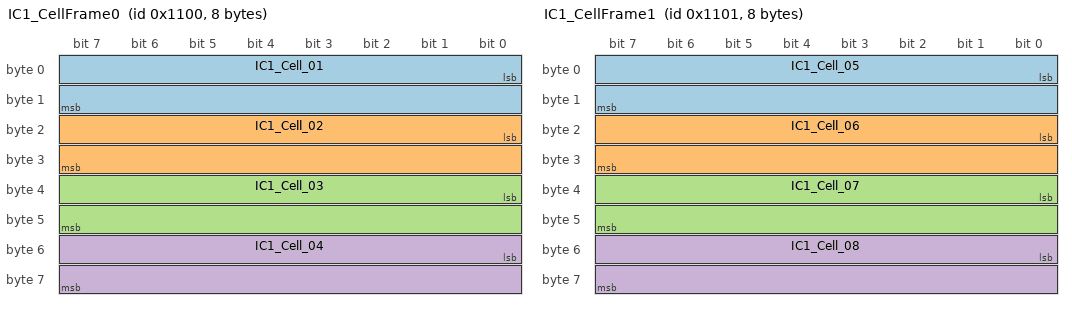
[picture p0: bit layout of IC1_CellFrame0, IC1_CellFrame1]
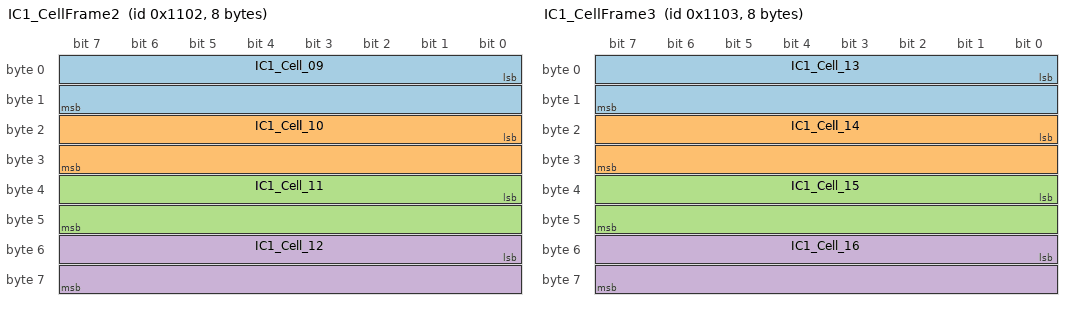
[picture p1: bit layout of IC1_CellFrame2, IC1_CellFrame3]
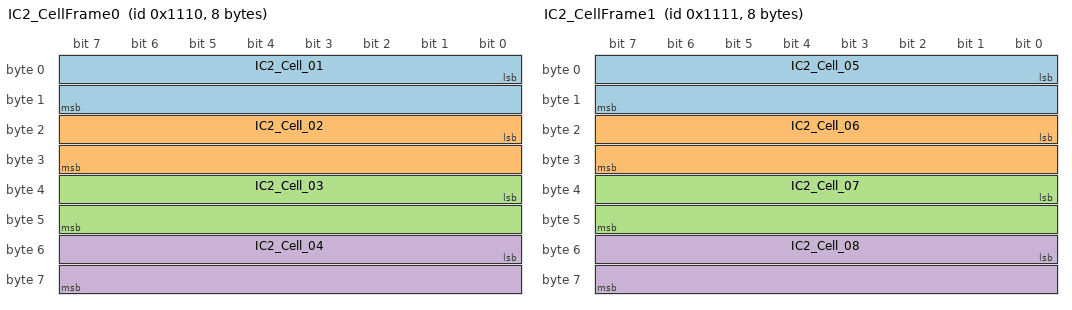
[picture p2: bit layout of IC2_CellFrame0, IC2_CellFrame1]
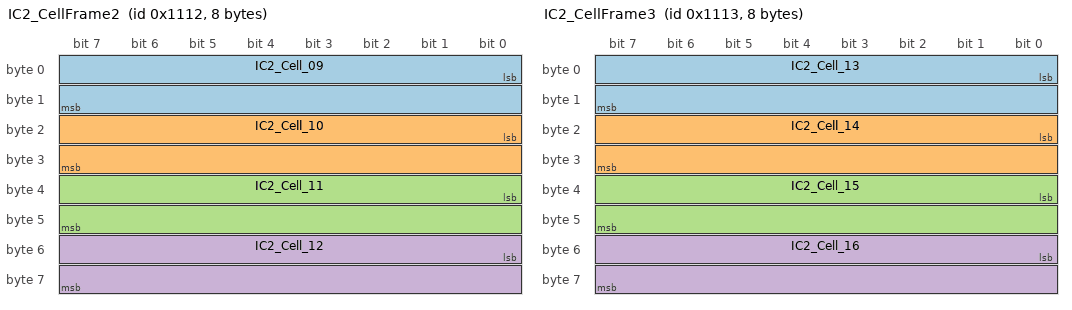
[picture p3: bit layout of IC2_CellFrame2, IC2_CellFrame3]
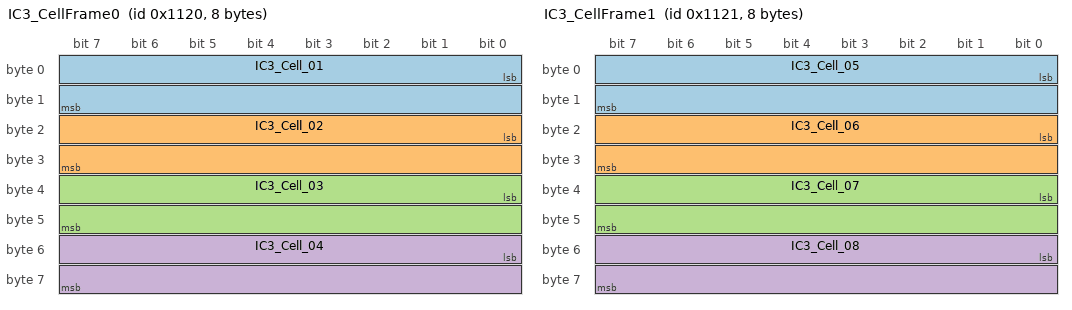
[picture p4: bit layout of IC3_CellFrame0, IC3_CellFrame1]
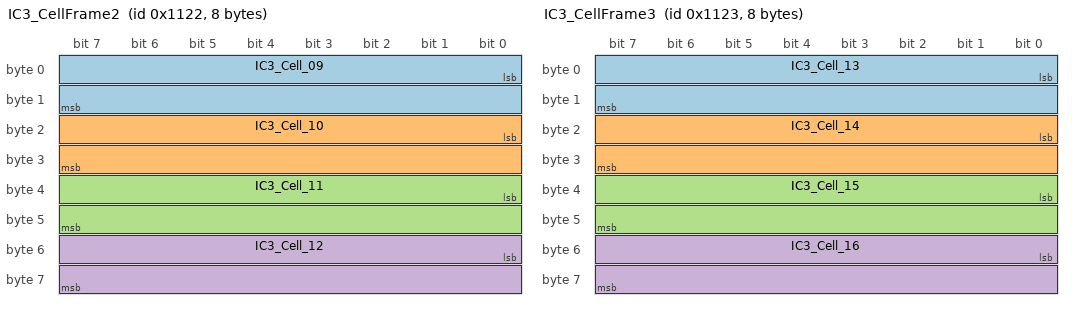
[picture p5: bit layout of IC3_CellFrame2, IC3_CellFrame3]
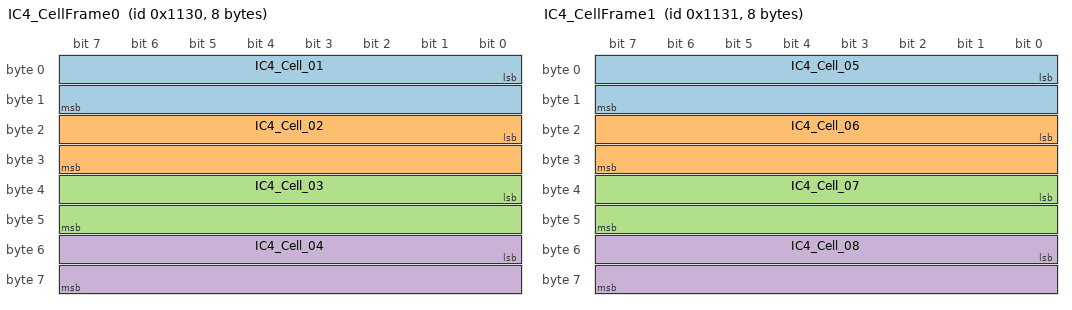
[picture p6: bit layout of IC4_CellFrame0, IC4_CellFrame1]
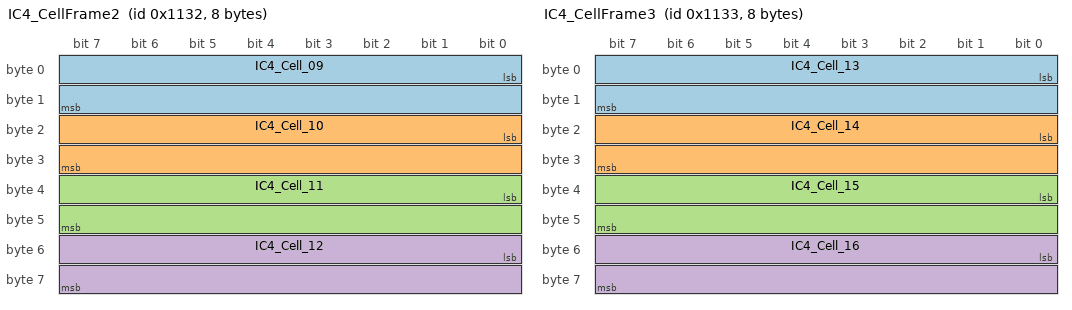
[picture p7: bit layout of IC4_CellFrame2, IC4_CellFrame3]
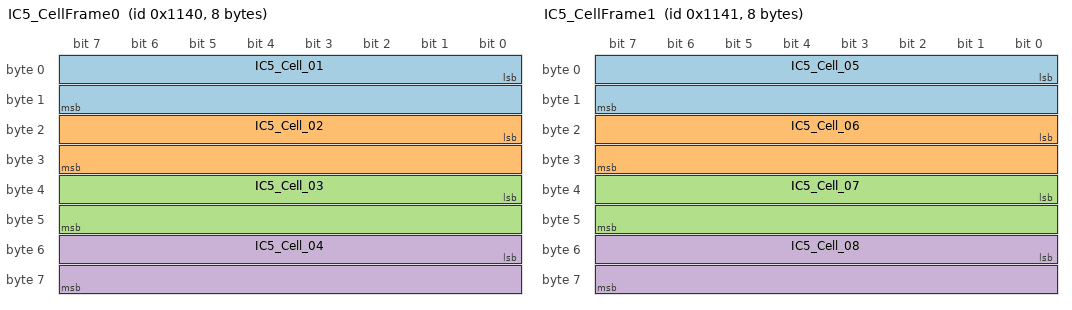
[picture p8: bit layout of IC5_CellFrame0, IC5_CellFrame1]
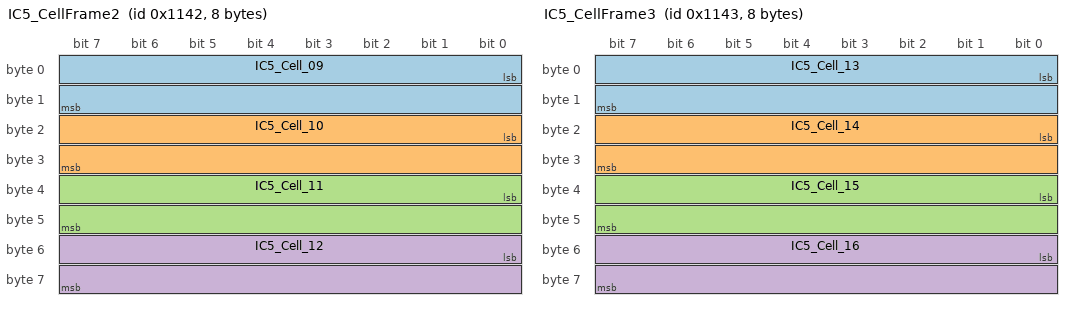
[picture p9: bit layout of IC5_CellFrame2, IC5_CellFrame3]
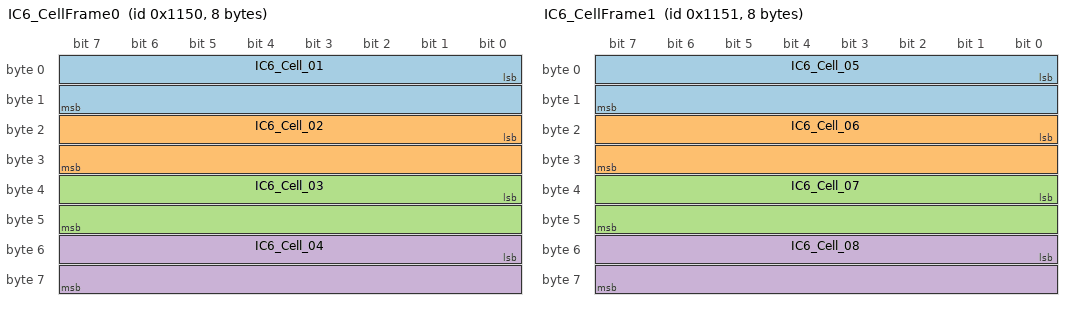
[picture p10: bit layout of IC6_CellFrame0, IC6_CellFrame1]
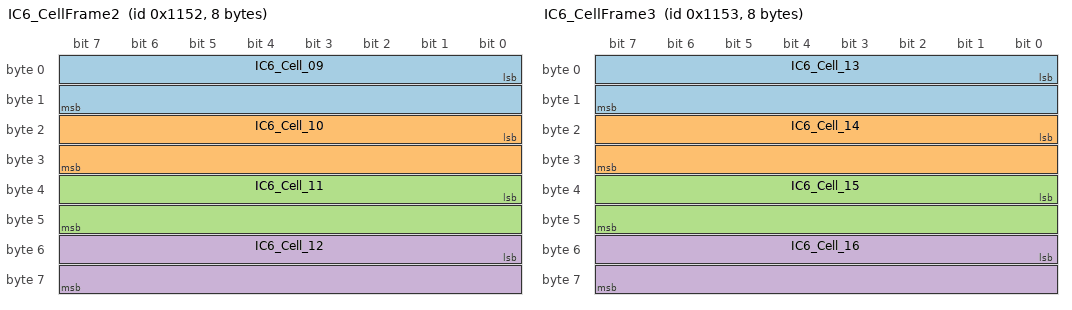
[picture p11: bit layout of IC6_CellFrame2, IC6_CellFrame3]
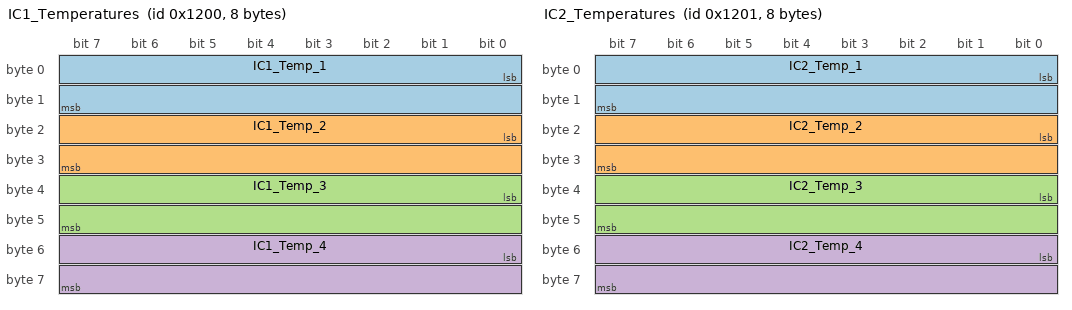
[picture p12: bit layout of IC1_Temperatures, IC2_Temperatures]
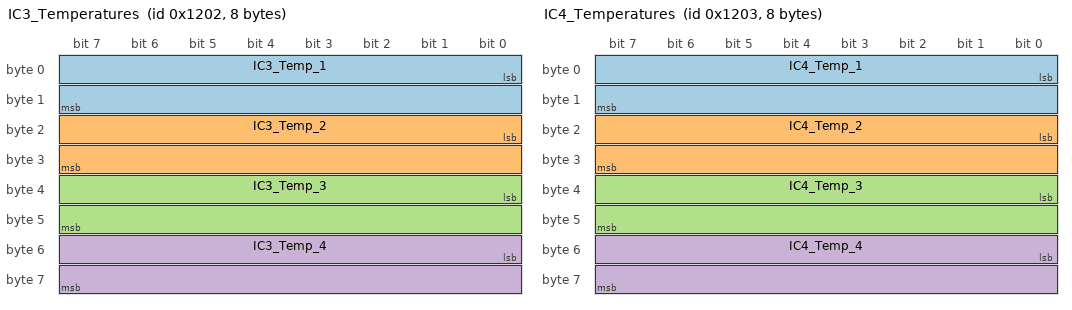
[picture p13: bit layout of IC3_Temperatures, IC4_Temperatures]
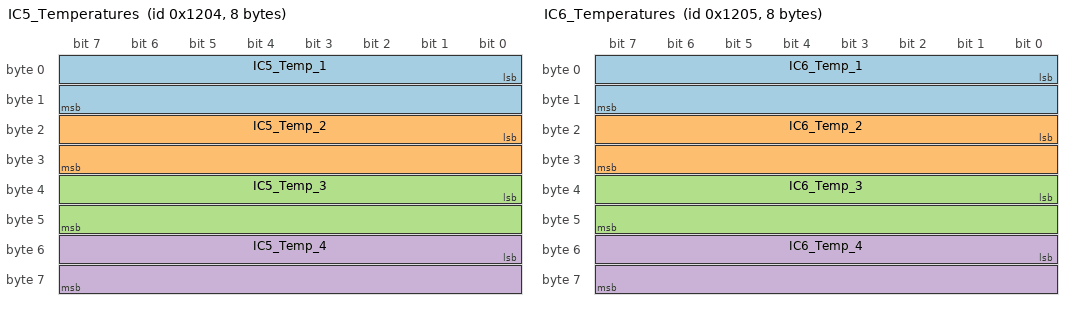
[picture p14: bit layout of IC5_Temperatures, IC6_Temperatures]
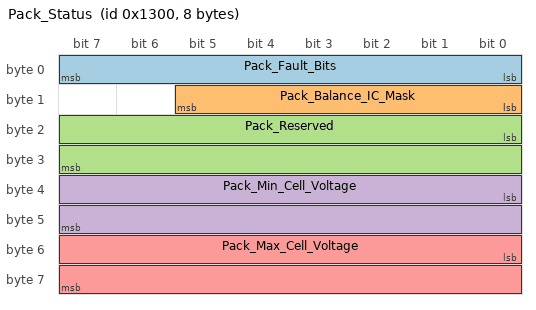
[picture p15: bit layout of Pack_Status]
VERSION ""

NS_ :

BS_:

BU_: BMS Host

BO_ 0x1100 IC1_CellFrame0: 8 BMS
 SG_ IC1_Cell_01 : 0|16@1+ (0.0001,0) [0|6.5535] "V" Host
 SG_ IC1_Cell_02 : 16|16@1+ (0.0001,0) [0|6.5535] "V" Host
 SG_ IC1_Cell_03 : 32|16@1+ (0.0001,0) [0|6.5535] "V" Host
 SG_ IC1_Cell_04 : 48|16@1+ (0.0001,0) [0|6.5535] "V" Host

BO_ 0x1101 IC1_CellFrame1: 8 BMS
 SG_ IC1_Cell_05 : 0|16@1+ (0.0001,0) [0|6.5535] "V" Host
 SG_ IC1_Cell_06 : 16|16@1+ (0.0001,0) [0|6.5535] "V" Host
 SG_ IC1_Cell_07 : 32|16@1+ (0.0001,0) [0|6.5535] "V" Host
 SG_ IC1_Cell_08 : 48|16@1+ (0.0001,0) [0|6.5535] "V" Host

BO_ 0x1102 IC1_CellFrame2: 8 BMS
 SG_ IC1_Cell_09 : 0|16@1+ (0.0001,0) [0|6.5535] "V" Host
 SG_ IC1_Cell_10 : 16|16@1+ (0.0001,0) [0|6.5535] "V" Host
 SG_ IC1_Cell_11 : 32|16@1+ (0.0001,0) [0|6.5535] "V" Host
 SG_ IC1_Cell_12 : 48|16@1+ (0.0001,0) [0|6.5535] "V" Host

BO_ 0x1103 IC1_CellFrame3: 8 BMS
 SG_ IC1_Cell_13 : 0|16@1+ (0.0001,0) [0|6.5535] "V" Host
 SG_ IC1_Cell_14 : 16|16@1+ (0.0001,0) [0|6.5535] "V" Host
 SG_ IC1_Cell_15 : 32|16@1+ (0.0001,0) [0|6.5535] "V" Host
 SG_ IC1_Cell_16 : 48|16@1+ (0.0001,0) [0|6.5535] "V" Host

BO_ 0x1104 IC1_CellFrame4: 8 BMS
 SG_ IC1_Cell_17 : 0|16@1+ (0.0001,0) [0|6.5535] "V" Host

BO_ 0x1110 IC2_CellFrame0: 8 BMS
 SG_ IC2_Cell_01 : 0|16@1+ (0.0001,0) [0|6.5535] "V" Host
 SG_ IC2_Cell_02 : 16|16@1+ (0.0001,0) [0|6.5535] "V" Host
 SG_ IC2_Cell_03 : 32|16@1+ (0.0001,0) [0|6.5535] "V" Host
 SG_ IC2_Cell_04 : 48|16@1+ (0.0001,0) [0|6.5535] "V" Host

BO_ 0x1111 IC2_CellFrame1: 8 BMS
 SG_ IC2_Cell_05 : 0|16@1+ (0.0001,0) [0|6.5535] "V" Host
 SG_ IC2_Cell_06 : 16|16@1+ (0.0001,0) [0|6.5535] "V" Host
 SG_ IC2_Cell_07 : 32|16@1+ (0.0001,0) [0|6.5535] "V" Host
 SG_ IC2_Cell_08 : 48|16@1+ (0.0001,0) [0|6.5535] "V" Host

BO_ 0x1112 IC2_CellFrame2: 8 BMS
 SG_ IC2_Cell_09 : 0|16@1+ (0.0001,0) [0|6.5535] "V" Host
 SG_ IC2_Cell_10 : 16|16@1+ (0.0001,0) [0|6.5535] "V" Host
 SG_ IC2_Cell_11 : 32|16@1+ (0.0001,0) [0|6.5535] "V" Host
 SG_ IC2_Cell_12 : 48|16@1+ (0.0001,0) [0|6.5535] "V" Host

BO_ 0x1113 IC2_CellFrame3: 8 BMS
 SG_ IC2_Cell_13 : 0|16@1+ (0.0001,0) [0|6.5535] "V" Host
 SG_ IC2_Cell_14 : 16|16@1+ (0.0001,0) [0|6.5535] "V" Host
 SG_ IC2_Cell_15 : 32|16@1+ (0.0001,0) [0|6.5535] "V" Host
 SG_ IC2_Cell_16 : 48|16@1+ (0.0001,0) [0|6.5535] "V" Host

BO_ 0x1114 IC2_CellFrame4: 8 BMS
 SG_ IC2_Cell_17 : 0|16@1+ (0.0001,0) [0|6.5535] "V" Host

BO_ 0x1120 IC3_CellFrame0: 8 BMS
 SG_ IC3_Cell_01 : 0|16@1+ (0.0001,0) [0|6.5535] "V" Host
 SG_ IC3_Cell_02 : 16|16@1+ (0.0001,0) [0|6.5535] "V" Host
 SG_ IC3_Cell_03 : 32|16@1+ (0.0001,0) [0|6.5535] "V" Host
 SG_ IC3_Cell_04 : 48|16@1+ (0.0001,0) [0|6.5535] "V" Host

BO_ 0x1121 IC3_CellFrame1: 8 BMS
 SG_ IC3_Cell_05 : 0|16@1+ (0.0001,0) [0|6.5535] "V" Host
 SG_ IC3_Cell_06 : 16|16@1+ (0.0001,0) [0|6.5535] "V" Host
 SG_ IC3_Cell_07 : 32|16@1+ (0.0001,0) [0|6.5535] "V" Host
 SG_ IC3_Cell_08 : 48|16@1+ (0.0001,0) [0|6.5535] "V" Host

BO_ 0x1122 IC3_CellFrame2: 8 BMS
 SG_ IC3_Cell_09 : 0|16@1+ (0.0001,0) [0|6.5535] "V" Host
 SG_ IC3_Cell_10 : 16|16@1+ (0.0001,0) [0|6.5535] "V" Host
 SG_ IC3_Cell_11 : 32|16@1+ (0.0001,0) [0|6.5535] "V" Host
 SG_ IC3_Cell_12 : 48|16@1+ (0.0001,0) [0|6.5535] "V" Host

BO_ 0x1123 IC3_CellFrame3: 8 BMS
 SG_ IC3_Cell_13 : 0|16@1+ (0.0001,0) [0|6.5535] "V" Host
 SG_ IC3_Cell_14 : 16|16@1+ (0.0001,0) [0|6.5535] "V" Host
 SG_ IC3_Cell_15 : 32|16@1+ (0.0001,0) [0|6.5535] "V" Host
 SG_ IC3_Cell_16 : 48|16@1+ (0.0001,0) [0|6.5535] "V" Host

BO_ 0x1124 IC3_CellFrame4: 8 BMS
 SG_ IC3_Cell_17 : 0|16@1+ (0.0001,0) [0|6.5535] "V" Host

BO_ 0x1130 IC4_CellFrame0: 8 BMS
 SG_ IC4_Cell_01 : 0|16@1+ (0.0001,0) [0|6.5535] "V" Host
 SG_ IC4_Cell_02 : 16|16@1+ (0.0001,0) [0|6.5535] "V" Host
 SG_ IC4_Cell_03 : 32|16@1+ (0.0001,0) [0|6.5535] "V" Host
 SG_ IC4_Cell_04 : 48|16@1+ (0.0001,0) [0|6.5535] "V" Host

BO_ 0x1131 IC4_CellFrame1: 8 BMS
 SG_ IC4_Cell_05 : 0|16@1+ (0.0001,0) [0|6.5535] "V" Host
 SG_ IC4_Cell_06 : 16|16@1+ (0.0001,0) [0|6.5535] "V" Host
 SG_ IC4_Cell_07 : 32|16@1+ (0.0001,0) [0|6.5535] "V" Host
 SG_ IC4_Cell_08 : 48|16@1+ (0.0001,0) [0|6.5535] "V" Host

BO_ 0x1132 IC4_CellFrame2: 8 BMS
 SG_ IC4_Cell_09 : 0|16@1+ (0.0001,0) [0|6.5535] "V" Host
 SG_ IC4_Cell_10 : 16|16@1+ (0.0001,0) [0|6.5535] "V" Host
 SG_ IC4_Cell_11 : 32|16@1+ (0.0001,0) [0|6.5535] "V" Host
 SG_ IC4_Cell_12 : 48|16@1+ (0.0001,0) [0|6.5535] "V" Host

BO_ 0x1133 IC4_CellFrame3: 8 BMS
 SG_ IC4_Cell_13 : 0|16@1+ (0.0001,0) [0|6.5535] "V" Host
 SG_ IC4_Cell_14 : 16|16@1+ (0.0001,0) [0|6.5535] "V" Host
 SG_ IC4_Cell_15 : 32|16@1+ (0.0001,0) [0|6.5535] "V" Host
 SG_ IC4_Cell_16 : 48|16@1+ (0.0001,0) [0|6.5535] "V" Host

BO_ 0x1134 IC4_CellFrame4: 8 BMS
 SG_ IC4_Cell_17 : 0|16@1+ (0.0001,0) [0|6.5535] "V" Host

BO_ 0x1140 IC5_CellFrame0: 8 BMS
 SG_ IC5_Cell_01 : 0|16@1+ (0.0001,0) [0|6.5535] "V" Host
 SG_ IC5_Cell_02 : 16|16@1+ (0.0001,0) [0|6.5535] "V" Host
 SG_ IC5_Cell_03 : 32|16@1+ (0.0001,0) [0|6.5535] "V" Host
 SG_ IC5_Cell_04 : 48|16@1+ (0.0001,0) [0|6.5535] "V" Host

BO_ 0x1141 IC5_CellFrame1: 8 BMS
 SG_ IC5_Cell_05 : 0|16@1+ (0.0001,0) [0|6.5535] "V" Host
 SG_ IC5_Cell_06 : 16|16@1+ (0.0001,0) [0|6.5535] "V" Host
 SG_ IC5_Cell_07 : 32|16@1+ (0.0001,0) [0|6.5535] "V" Host
 SG_ IC5_Cell_08 : 48|16@1+ (0.0001,0) [0|6.5535] "V" Host

BO_ 0x1142 IC5_CellFrame2: 8 BMS
 SG_ IC5_Cell_09 : 0|16@1+ (0.0001,0) [0|6.5535] "V" Host
 SG_ IC5_Cell_10 : 16|16@1+ (0.0001,0) [0|6.5535] "V" Host
 SG_ IC5_Cell_11 : 32|16@1+ (0.0001,0) [0|6.5535] "V" Host
 SG_ IC5_Cell_12 : 48|16@1+ (0.0001,0) [0|6.5535] "V" Host

BO_ 0x1143 IC5_CellFrame3: 8 BMS
 SG_ IC5_Cell_13 : 0|16@1+ (0.0001,0) [0|6.5535] "V" Host
 SG_ IC5_Cell_14 : 16|16@1+ (0.0001,0) [0|6.5535] "V" Host
 SG_ IC5_Cell_15 : 32|16@1+ (0.0001,0) [0|6.5535] "V" Host
 SG_ IC5_Cell_16 : 48|16@1+ (0.0001,0) [0|6.5535] "V" Host

BO_ 0x1144 IC5_CellFrame4: 8 BMS
 SG_ IC5_Cell_17 : 0|16@1+ (0.0001,0) [0|6.5535] "V" Host

BO_ 0x1150 IC6_CellFrame0: 8 BMS
 SG_ IC6_Cell_01 : 0|16@1+ (0.0001,0) [0|6.5535] "V" Host
 SG_ IC6_Cell_02 : 16|16@1+ (0.0001,0) [0|6.5535] "V" Host
 SG_ IC6_Cell_03 : 32|16@1+ (0.0001,0) [0|6.5535] "V" Host
 SG_ IC6_Cell_04 : 48|16@1+ (0.0001,0) [0|6.5535] "V" Host

BO_ 0x1151 IC6_CellFrame1: 8 BMS
 SG_ IC6_Cell_05 : 0|16@1+ (0.0001,0) [0|6.5535] "V" Host
 SG_ IC6_Cell_06 : 16|16@1+ (0.0001,0) [0|6.5535] "V" Host
 SG_ IC6_Cell_07 : 32|16@1+ (0.0001,0) [0|6.5535] "V" Host
 SG_ IC6_Cell_08 : 48|16@1+ (0.0001,0) [0|6.5535] "V" Host

BO_ 0x1152 IC6_CellFrame2: 8 BMS
 SG_ IC6_Cell_09 : 0|16@1+ (0.0001,0) [0|6.5535] "V" Host
 SG_ IC6_Cell_10 : 16|16@1+ (0.0001,0) [0|6.5535] "V" Host
 SG_ IC6_Cell_11 : 32|16@1+ (0.0001,0) [0|6.5535] "V" Host
 SG_ IC6_Cell_12 : 48|16@1+ (0.0001,0) [0|6.5535] "V" Host

BO_ 0x1153 IC6_CellFrame3: 8 BMS
 SG_ IC6_Cell_13 : 0|16@1+ (0.0001,0) [0|6.5535] "V" Host
 SG_ IC6_Cell_14 : 16|16@1+ (0.0001,0) [0|6.5535] "V" Host
 SG_ IC6_Cell_15 : 32|16@1+ (0.0001,0) [0|6.5535] "V" Host
 SG_ IC6_Cell_16 : 48|16@1+ (0.0001,0) [0|6.5535] "V" Host

BO_ 0x1154 IC6_CellFrame4: 8 BMS
 SG_ IC6_Cell_17 : 0|16@1+ (0.0001,0) [0|6.5535] "V" Host

BO_ 0x1200 IC1_Temperatures: 8 BMS
 SG_ IC1_Temp_1 : 0|16@1- (0.1,0) [-3276.8|3276.7] "degC" Host
 SG_ IC1_Temp_2 : 16|16@1- (0.1,0) [-3276.8|3276.7] "degC" Host
 SG_ IC1_Temp_3 : 32|16@1- (0.1,0) [-3276.8|3276.7] "degC" Host
 SG_ IC1_Temp_4 : 48|16@1- (0.1,0) [-3276.8|3276.7] "degC" Host

BO_ 0x1201 IC2_Temperatures: 8 BMS
 SG_ IC2_Temp_1 : 0|16@1- (0.1,0) [-3276.8|3276.7] "degC" Host
 SG_ IC2_Temp_2 : 16|16@1- (0.1,0) [-3276.8|3276.7] "degC" Host
 SG_ IC2_Temp_3 : 32|16@1- (0.1,0) [-3276.8|3276.7] "degC" Host
 SG_ IC2_Temp_4 : 48|16@1- (0.1,0) [-3276.8|3276.7] "degC" Host

BO_ 0x1202 IC3_Temperatures: 8 BMS
 SG_ IC3_Temp_1 : 0|16@1- (0.1,0) [-3276.8|3276.7] "degC" Host
 SG_ IC3_Temp_2 : 16|16@1- (0.1,0) [-3276.8|3276.7] "degC" Host
 SG_ IC3_Temp_3 : 32|16@1- (0.1,0) [-3276.8|3276.7] "degC" Host
 SG_ IC3_Temp_4 : 48|16@1- (0.1,0) [-3276.8|3276.7] "degC" Host

BO_ 0x1203 IC4_Temperatures: 8 BMS
 SG_ IC4_Temp_1 : 0|16@1- (0.1,0) [-3276.8|3276.7] "degC" Host
 SG_ IC4_Temp_2 : 16|16@1- (0.1,0) [-3276.8|3276.7] "degC" Host
 SG_ IC4_Temp_3 : 32|16@1- (0.1,0) [-3276.8|3276.7] "degC" Host
 SG_ IC4_Temp_4 : 48|16@1- (0.1,0) [-3276.8|3276.7] "degC" Host

BO_ 0x1204 IC5_Temperatures: 8 BMS
 SG_ IC5_Temp_1 : 0|16@1- (0.1,0) [-3276.8|3276.7] "degC" Host
 SG_ IC5_Temp_2 : 16|16@1- (0.1,0) [-3276.8|3276.7] "degC" Host
 SG_ IC5_Temp_3 : 32|16@1- (0.1,0) [-3276.8|3276.7] "degC" Host
 SG_ IC5_Temp_4 : 48|16@1- (0.1,0) [-3276.8|3276.7] "degC" Host

BO_ 0x1205 IC6_Temperatures: 8 BMS
 SG_ IC6_Temp_1 : 0|16@1- (0.1,0) [-3276.8|3276.7] "degC" Host
 SG_ IC6_Temp_2 : 16|16@1- (0.1,0) [-3276.8|3276.7] "degC" Host
 SG_ IC6_Temp_3 : 32|16@1- (0.1,0) [-3276.8|3276.7] "degC" Host
 SG_ IC6_Temp_4 : 48|16@1- (0.1,0) [-3276.8|3276.7] "degC" Host

BO_ 0x1300 Pack_Status: 8 BMS
 SG_ Pack_Fault_Bits : 0|8@1+ (1,0) [0|255] "" Host
 SG_ Pack_Balance_IC_Mask : 8|6@1+ (1,0) [0|63] "" Host
 SG_ Pack_Reserved : 16|16@1+ (1,0) [0|0] "" Host
 SG_ Pack_Min_Cell_Voltage : 32|16@1+ (0.0001,0) [0|6.5535] "V" Host
 SG_ Pack_Max_Cell_Voltage : 48|16@1+ (0.0001,0) [0|6.5535] "V" Host

BO_ 0x1400 IC1_Balance: 8 BMS
 SG_ IC1_Balance_Mask : 0|17@1+ (1,0) [0|131071] "" Host

BO_ 0x1401 IC2_Balance: 8 BMS
 SG_ IC2_Balance_Mask : 0|17@1+ (1,0) [0|131071] "" Host

BO_ 0x1402 IC3_Balance: 8 BMS
 SG_ IC3_Balance_Mask : 0|17@1+ (1,0) [0|131071] "" Host

BO_ 0x1403 IC4_Balance: 8 BMS
 SG_ IC4_Balance_Mask : 0|17@1+ (1,0) [0|131071] "" Host

BO_ 0x1404 IC5_Balance: 8 BMS
 SG_ IC5_Balance_Mask : 0|17@1+ (1,0) [0|131071] "" Host

BO_ 0x1405 IC6_Balance: 8 BMS
 SG_ IC6_Balance_Mask : 0|17@1+ (1,0) [0|131071] "" Host

CM_ BO_ 0x1100 "IC1 Cells 1-4, 100uV/bit";
CM_ BO_ 0x1101 "IC1 Cells 5-8, 100uV/bit";
CM_ BO_ 0x1102 "IC1 Cells 9-12, 100uV/bit";
CM_ BO_ 0x1103 "IC1 Cells 13-16, 100uV/bit";
CM_ BO_ 0x1104 "IC1 Cell 17, 100uV/bit";

CM_ BO_ 0x1200 "IC1 Temperatures (NTC 1-4), 0.1 degC/bit";
CM_ BO_ 0x1300 "Pack-level BMS Status aggregated from all ICs (Faults, Balance IC mask, Min/Max Voltage)";
CM_ BO_ 0x1400 "IC1 Cell Balance Status (17-bit mask)";
CM_ BO_ 0x1150 "IC6 Cells 1-4, 100uV/bit";
CM_ BO_ 0x1151 "IC6 Cells 5-8, 100uV/bit";
CM_ BO_ 0x1152 "IC6 Cells 9-12, 100uV/bit";
CM_ BO_ 0x1153 "IC6 Cells 13-16, 100uV/bit";
CM_ BO_ 0x1154 "IC6 Cell 17, 100uV/bit";
CM_ BO_ 0x1205 "IC6 Temperatures (NTC 1-4), 0.1 degC/bit";
CM_ BO_ 0x1405 "IC6 Cell Balance Status (17-bit mask)";

CM_ SG_ 0x1300 Pack_Fault_Bits "Bit 0: !BMS_OK, Bit 1: Under Temp, Bit 2: Over Temp, Bit 3: Cell Voltage OOR, Bit 4: Open Wire";
CM_ SG_ 0x1300 Pack_Balance_IC_Mask "6-bit mask: each bit indicates if the corresponding IC has cells being balanced";
CM_ SG_ 0x1300 Pack_Min_Cell_Voltage "Minimum cell voltage across all ICs, 100uV/bit";
CM_ SG_ 0x1300 Pack_Max_Cell_Voltage "Maximum cell voltage across all ICs, 100uV/bit";

BA_DEF_  "BusType" STRING ;
BA_DEF_DEF_  "BusType" "CAN";
